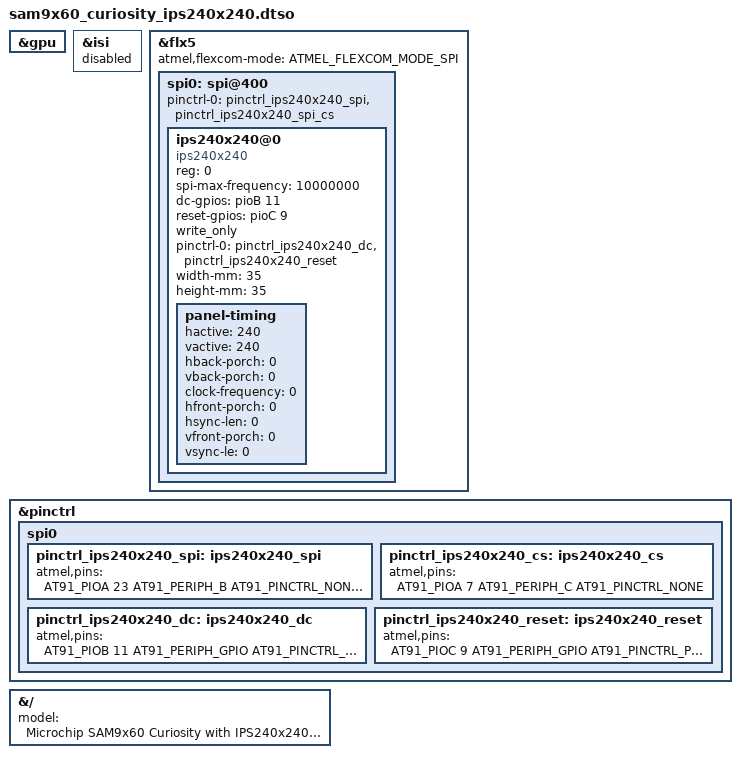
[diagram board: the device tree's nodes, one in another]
// SPDX-License-Identifier: (GPL-2.0+ OR MIT)
/*
 * Device Tree file for SAM9X60-CURIOSITY board
 * overlay blob for IPS240x240 SPI Display
 *
 * Copyright (C) 2024 Microchip Technology, Inc. and its subsidiaries
 * Author: Darren Wenn <darren.wenn@microchip.com>
 *
 */
/dts-v1/;
/plugin/;

#include <dt-bindings/pinctrl/at91.h>
#include <dt-bindings/gpio/gpio.h>
#include <dt-bindings/mfd/atmel-flexcom.h>

&gpu {
	status = "okay";
};


&isi {
	status = "disabled";
};

&flx5 {
    atmel,flexcom-mode = <ATMEL_FLEXCOM_MODE_SPI>;
    status = "okay";
    
    spi0: spi@400 {
        #address-cells = <1>;
        #size-cells = <0>;
        status = "okay";
        
        pinctrl-names = "default";
        pinctrl-0 = <&pinctrl_ips240x240_spi &pinctrl_ips240x240_spi_cs>;

        ips240x240@0 {
            compatible = "ips240x240", "panel-mipi-dbi-spi";
            reg = <0>;
            spi-max-frequency = <10000000>;

            dc-gpios = <&pioB 11 GPIO_ACTIVE_HIGH>;
            reset-gpios = <&pioC 9 GPIO_ACTIVE_HIGH>;
            write_only;

            pinctrl-names = "default";
            pinctrl-0 = <&pinctrl_ips240x240_dc &pinctrl_ips240x240_reset>;
            
            width-mm = <35>;
            height-mm = <35>;

            panel-timing {
                hactive = <240>;
                vactive = <240>;
                hback-porch = <0>;
                vback-porch = <0>;
                clock-frequency = <0>;
                hfront-porch = <0>;
                hsync-len = <0>;
                vfront-porch = <0>;
                vsync-le = <0>;
            };
        };   
    };
};

&pinctrl {
    spi0 {
        pinctrl_ips240x240_spi: ips240x240_spi {
            atmel,pins = <AT91_PIOA 23 AT91_PERIPH_B AT91_PINCTRL_NONE
                          AT91_PIOA 21 AT91_PERIPH_B AT91_PINCTRL_NONE
                          AT91_PIOA 22 AT91_PERIPH_B AT91_PINCTRL_NONE>;
        };
        
        pinctrl_ips240x240_cs: ips240x240_cs {
 	    atmel,pins = <AT91_PIOA 7 AT91_PERIPH_C AT91_PINCTRL_NONE>;
        };
    
        pinctrl_ips240x240_dc: ips240x240_dc {
            atmel,pins = <AT91_PIOB 11 AT91_PERIPH_GPIO AT91_PINCTRL_PULL_DOWN>;
        };
        
        pinctrl_ips240x240_reset: ips240x240_reset {
            atmel,pins = <AT91_PIOC 9 AT91_PERIPH_GPIO AT91_PINCTRL_PULL_DOWN>;
        };
    };
};

&{/} {
        model = "Microchip SAM9x60 Curiosity with IPS240x240 Display";
};

